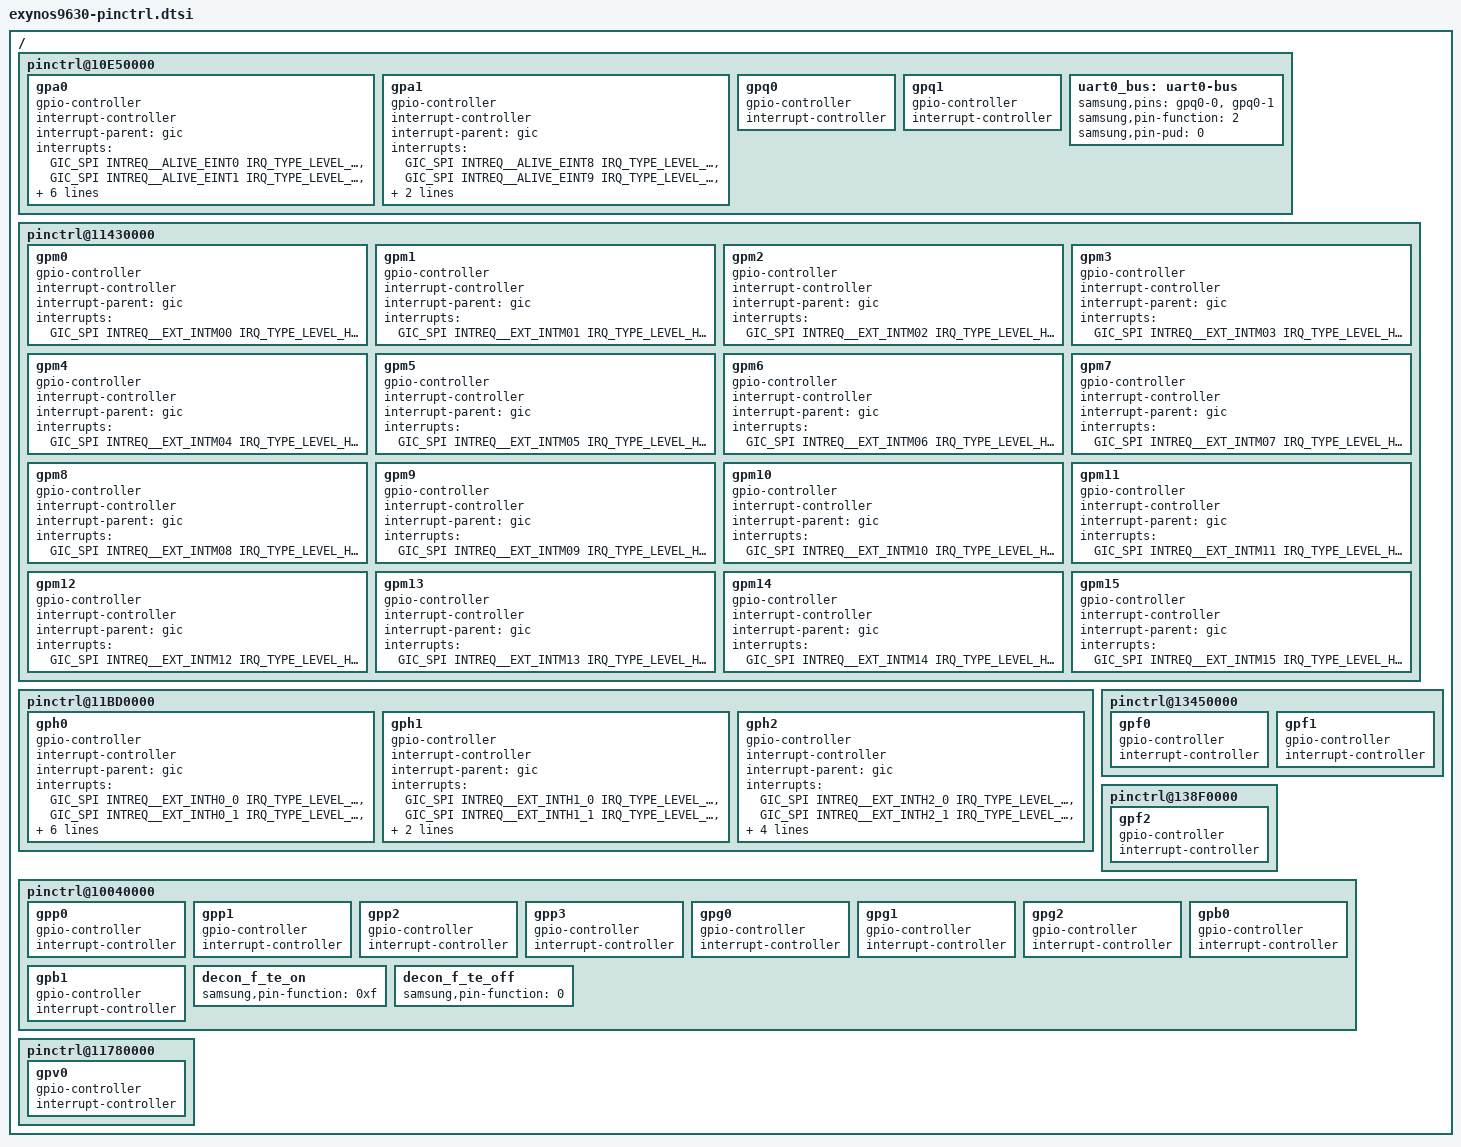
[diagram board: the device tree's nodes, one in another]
/*
 * Samsung's Exynos9630 SoC pin-mux and pin-config device tree source
 *
 * Copyright (c) 2019 Samsung Electronics Co., Ltd.
 *		http://www.samsung.com
 *
 * Samsung's Exynos9630 SoC pin-mux and pin-config options are listed as device
 * tree nodes are listed in this file.
 *
 * This program is free software; you can redistribute it and/or modify
 * it under the terms of the GNU General Public License version 2 as
 * published by the Free Software Foundation.
 */

/ {
	/* ALIVE */
	pinctrl@10E50000 {
		gpa0: gpa0 {
			gpio-controller;
			#gpio-cells = <2>;

			interrupt-controller;
			#interrupt-cells = <3>;
			interrupt-parent = <&gic>;
			interrupts = <GIC_SPI INTREQ__ALIVE_EINT0 IRQ_TYPE_LEVEL_HIGH>,
				     <GIC_SPI INTREQ__ALIVE_EINT1 IRQ_TYPE_LEVEL_HIGH>,
				     <GIC_SPI INTREQ__ALIVE_EINT2 IRQ_TYPE_LEVEL_HIGH>,
				     <GIC_SPI INTREQ__ALIVE_EINT3 IRQ_TYPE_LEVEL_HIGH>,
				     <GIC_SPI INTREQ__ALIVE_EINT4 IRQ_TYPE_LEVEL_HIGH>,
				     <GIC_SPI INTREQ__ALIVE_EINT5 IRQ_TYPE_LEVEL_HIGH>,
				     <GIC_SPI INTREQ__ALIVE_EINT6 IRQ_TYPE_LEVEL_HIGH>,
				     <GIC_SPI INTREQ__ALIVE_EINT7 IRQ_TYPE_LEVEL_HIGH>;
		};

		gpa1: gpa1 {
			gpio-controller;
			#gpio-cells = <2>;

			interrupt-controller;
			#interrupt-cells = <3>;
			interrupt-parent = <&gic>;
			interrupts = <GIC_SPI INTREQ__ALIVE_EINT8 IRQ_TYPE_LEVEL_HIGH>,
				     <GIC_SPI INTREQ__ALIVE_EINT9 IRQ_TYPE_LEVEL_HIGH>,
				     <GIC_SPI INTREQ__ALIVE_EINT10 IRQ_TYPE_LEVEL_HIGH>,
				     <GIC_SPI INTREQ__ALIVE_EINT11 IRQ_TYPE_LEVEL_HIGH>;
		};

		gpq0: gpq0 {
			gpio-controller;
			#gpio-cells = <2>;

			interrupt-controller;
			#interrupt-cells = <2>;
		};

		gpq1: gpq1 {
			gpio-controller;
			#gpio-cells = <2>;

			interrupt-controller;
			#interrupt-cells = <2>;
		};

		/* USI_PERIC0_UART_DBG */
		uart0_bus: uart0-bus {
			samsung,pins = "gpq0-0", "gpq0-1";
			samsung,pin-function = <2>;
			samsung,pin-pud = <0>;
		};
	};

	/* CMGP */
	pinctrl@11430000 {
		gpm0: gpm0 {
			gpio-controller;
			#gpio-cells = <2>;

			interrupt-controller;
			#interrupt-cells = <3>;
			interrupt-parent = <&gic>;
			interrupts = <GIC_SPI INTREQ__EXT_INTM00 IRQ_TYPE_LEVEL_HIGH>;
		};

		gpm1: gpm1 {
			gpio-controller;
			#gpio-cells = <2>;

			interrupt-controller;
			#interrupt-cells = <3>;
			interrupt-parent = <&gic>;
			interrupts = <GIC_SPI INTREQ__EXT_INTM01 IRQ_TYPE_LEVEL_HIGH>;
		};

		gpm2: gpm2 {
			gpio-controller;
			#gpio-cells = <2>;

			interrupt-controller;
			#interrupt-cells = <3>;
			interrupt-parent = <&gic>;
			interrupts = <GIC_SPI INTREQ__EXT_INTM02 IRQ_TYPE_LEVEL_HIGH>;
		};

		gpm3: gpm3 {
			gpio-controller;
			#gpio-cells = <2>;

			interrupt-controller;
			#interrupt-cells = <3>;
			interrupt-parent = <&gic>;
			interrupts = <GIC_SPI INTREQ__EXT_INTM03 IRQ_TYPE_LEVEL_HIGH>;
		};

		gpm4: gpm4 {
			gpio-controller;
			#gpio-cells = <2>;

			interrupt-controller;
			#interrupt-cells = <3>;
			interrupt-parent = <&gic>;
			interrupts = <GIC_SPI INTREQ__EXT_INTM04 IRQ_TYPE_LEVEL_HIGH>;
		};

		gpm5: gpm5 {
			gpio-controller;
			#gpio-cells = <2>;

			interrupt-controller;
			#interrupt-cells = <3>;
			interrupt-parent = <&gic>;
			interrupts = <GIC_SPI INTREQ__EXT_INTM05 IRQ_TYPE_LEVEL_HIGH>;
		};

		gpm6: gpm6 {
			gpio-controller;
			#gpio-cells = <2>;

			interrupt-controller;
			#interrupt-cells = <3>;
			interrupt-parent = <&gic>;
			interrupts = <GIC_SPI INTREQ__EXT_INTM06 IRQ_TYPE_LEVEL_HIGH>;
		};

		gpm7: gpm7 {
			gpio-controller;
			#gpio-cells = <2>;

			interrupt-controller;
			#interrupt-cells = <3>;
			interrupt-parent = <&gic>;
			interrupts = <GIC_SPI INTREQ__EXT_INTM07 IRQ_TYPE_LEVEL_HIGH>;
		};

		gpm8: gpm8 {
			gpio-controller;
			#gpio-cells = <2>;

			interrupt-controller;
			#interrupt-cells = <3>;
			interrupt-parent = <&gic>;
			interrupts = <GIC_SPI INTREQ__EXT_INTM08 IRQ_TYPE_LEVEL_HIGH>;
		};

		gpm9: gpm9 {
			gpio-controller;
			#gpio-cells = <2>;

			interrupt-controller;
			#interrupt-cells = <3>;
			interrupt-parent = <&gic>;
			interrupts = <GIC_SPI INTREQ__EXT_INTM09 IRQ_TYPE_LEVEL_HIGH>;
		};

		gpm10: gpm10 {
			gpio-controller;
			#gpio-cells = <2>;

			interrupt-controller;
			#interrupt-cells = <3>;
			interrupt-parent = <&gic>;
			interrupts = <GIC_SPI INTREQ__EXT_INTM10 IRQ_TYPE_LEVEL_HIGH>;
		};

		gpm11: gpm11 {
			gpio-controller;
			#gpio-cells = <2>;

			interrupt-controller;
			#interrupt-cells = <3>;
			interrupt-parent = <&gic>;
			interrupts = <GIC_SPI INTREQ__EXT_INTM11 IRQ_TYPE_LEVEL_HIGH>;
		};

		gpm12: gpm12 {
			gpio-controller;
			#gpio-cells = <2>;

			interrupt-controller;
			#interrupt-cells = <3>;
			interrupt-parent = <&gic>;
			interrupts = <GIC_SPI INTREQ__EXT_INTM12 IRQ_TYPE_LEVEL_HIGH>;
		};

		gpm13: gpm13 {
			gpio-controller;
			#gpio-cells = <2>;

			interrupt-controller;
			#interrupt-cells = <3>;
			interrupt-parent = <&gic>;
			interrupts = <GIC_SPI INTREQ__EXT_INTM13 IRQ_TYPE_LEVEL_HIGH>;
		};

		gpm14: gpm14 {
			gpio-controller;
			#gpio-cells = <2>;

			interrupt-controller;
			#interrupt-cells = <3>;
			interrupt-parent = <&gic>;
			interrupts = <GIC_SPI INTREQ__EXT_INTM14 IRQ_TYPE_LEVEL_HIGH>;
		};

		gpm15: gpm15 {
			gpio-controller;
			#gpio-cells = <2>;

			interrupt-controller;
			#interrupt-cells = <3>;
			interrupt-parent = <&gic>;
			interrupts = <GIC_SPI INTREQ__EXT_INTM15 IRQ_TYPE_LEVEL_HIGH>;
		};
	};

	/* CHUB */
	pinctrl@11BD0000 {
		gph0: gph0 {
			gpio-controller;
			#gpio-cells = <2>;

			interrupt-controller;
			#interrupt-cells = <2>;
			interrupt-parent = <&gic>;
			interrupts = <GIC_SPI INTREQ__EXT_INTH0_0 IRQ_TYPE_LEVEL_HIGH>,
				     <GIC_SPI INTREQ__EXT_INTH0_1 IRQ_TYPE_LEVEL_HIGH>,
				     <GIC_SPI INTREQ__EXT_INTH0_2 IRQ_TYPE_LEVEL_HIGH>,
				     <GIC_SPI INTREQ__EXT_INTH0_3 IRQ_TYPE_LEVEL_HIGH>,
				     <GIC_SPI INTREQ__EXT_INTH0_4 IRQ_TYPE_LEVEL_HIGH>,
				     <GIC_SPI INTREQ__EXT_INTH0_5 IRQ_TYPE_LEVEL_HIGH>,
				     <GIC_SPI INTREQ__EXT_INTH0_6 IRQ_TYPE_LEVEL_HIGH>,
				     <GIC_SPI INTREQ__EXT_INTH0_7 IRQ_TYPE_LEVEL_HIGH>;
		};

		gph1: gph1 {
			gpio-controller;
			#gpio-cells = <2>;

			interrupt-controller;
			#interrupt-cells = <2>;
			interrupt-parent = <&gic>;
			interrupts = <GIC_SPI INTREQ__EXT_INTH1_0 IRQ_TYPE_LEVEL_HIGH>,
				     <GIC_SPI INTREQ__EXT_INTH1_1 IRQ_TYPE_LEVEL_HIGH>,
				     <GIC_SPI INTREQ__EXT_INTH1_2 IRQ_TYPE_LEVEL_HIGH>,
				     <GIC_SPI INTREQ__EXT_INTH1_3 IRQ_TYPE_LEVEL_HIGH>;
		};

		gph2: gph2 {
			gpio-controller;
			#gpio-cells = <2>;

			interrupt-controller;
			#interrupt-cells = <2>;
			interrupt-parent = <&gic>;
			interrupts = <GIC_SPI INTREQ__EXT_INTH2_0 IRQ_TYPE_LEVEL_HIGH>,
				     <GIC_SPI INTREQ__EXT_INTH2_1 IRQ_TYPE_LEVEL_HIGH>,
				     <GIC_SPI INTREQ__EXT_INTH2_2 IRQ_TYPE_LEVEL_HIGH>,
				     <GIC_SPI INTREQ__EXT_INTH2_3 IRQ_TYPE_LEVEL_HIGH>,
				     <GIC_SPI INTREQ__EXT_INTH2_4 IRQ_TYPE_LEVEL_HIGH>,
				     <GIC_SPI INTREQ__EXT_INTH2_5 IRQ_TYPE_LEVEL_HIGH>;
		};
	};

	/* HSI */
	pinctrl@13450000 {
		gpf0: gpf0 {
			gpio-controller;
			#gpio-cells = <2>;

			interrupt-controller;
			#interrupt-cells = <2>;
		};
		gpf1: gpf1 {
			gpio-controller;
			#gpio-cells = <2>;

			interrupt-controller;
			#interrupt-cells = <2>;
		};
	};

	/* MMCCARD */
	pinctrl@138F0000 {
		gpf2: gpf2 {
			gpio-controller;
			#gpio-cells = <2>;

			interrupt-controller;
			#interrupt-cells = <2>;
		};
	};

	/* PERI */
	pinctrl@10040000 {
		gpp0: gpp0 {
			gpio-controller;
			#gpio-cells = <2>;

			interrupt-controller;
			#interrupt-cells = <2>;
		};

		gpp1: gpp1 {
			gpio-controller;
			#gpio-cells = <2>;

			interrupt-controller;
			#interrupt-cells = <2>;
		};

		gpp2: gpp2 {
			gpio-controller;
			#gpio-cells = <2>;

			interrupt-controller;
			#interrupt-cells = <2>;
		};

		gpp3: gpp3 {
			gpio-controller;
			#gpio-cells = <2>;

			interrupt-controller;
			#interrupt-cells = <2>;
		};

		gpg0: gpg0 {
			gpio-controller;
			#gpio-cells = <2>;

			interrupt-controller;
			#interrupt-cells = <2>;
		};

		gpg1: gpg1 {
			gpio-controller;
			#gpio-cells = <2>;

			interrupt-controller;
			#interrupt-cells = <2>;
		};

		gpg2: gpg2 {
			gpio-controller;
			#gpio-cells = <2>;

			interrupt-controller;
			#interrupt-cells = <2>;
		};

		gpb0: gpb0 {
			gpio-controller;
			#gpio-cells = <2>;

			interrupt-controller;
			#interrupt-cells = <2>;
		};

		gpb1: gpb1 {
			gpio-controller;
			#gpio-cells = <2>;

			interrupt-controller;
			#interrupt-cells = <2>;
		      };

		decon_f_te_on: decon_f_te_on {
		       /* samsung,pins = "gpg0-1"; */
		       samsung,pin-function = <0xf>;
	       };

		decon_f_te_off: decon_f_te_off {
			/* samsung,pins = "gpg0-1"; */
			samsung,pin-function = <0>;
		};

	};

	/* VTS */
	pinctrl@11780000 {
		gpv0: gpv0 {
			gpio-controller;
			#gpio-cells = <2>;

			interrupt-controller;
			#interrupt-cells = <2>;
		};
	};
};
